# PRU_ICSSG0_PR1_ICSS_INTC_INTC_SLV register map
Vendor: Texas Instruments
Peripheral module from a debugger description file (folder am243x).
Registers are 32-bit, read-write, reset 0x0 unless marked. A register's access mark holds for its fields unless they carry their own. Offsets are as the file gives them; lines under a group give offsets from that group; [hi:lo] are bit positions; {n}, {i} and the like mark numbered series; 'fields as' and 'values as' point back to an identical list; <NAME> marks a mode.

## PRU_ICSSG0_PR1_ICSS_INTC_INTC_SLV
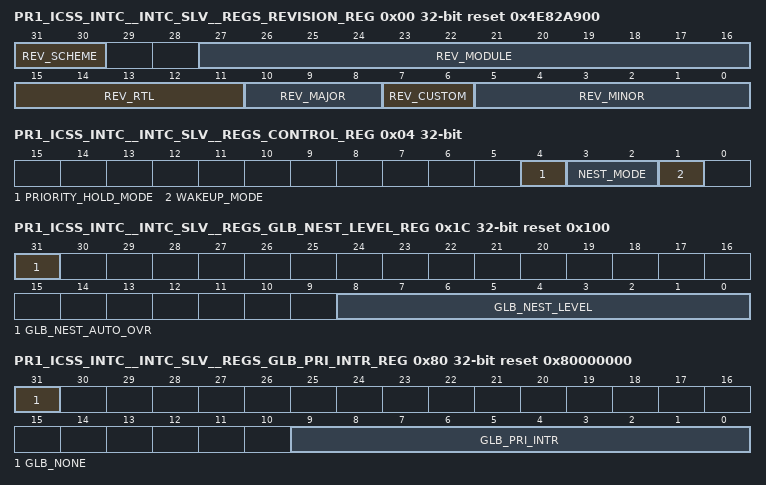
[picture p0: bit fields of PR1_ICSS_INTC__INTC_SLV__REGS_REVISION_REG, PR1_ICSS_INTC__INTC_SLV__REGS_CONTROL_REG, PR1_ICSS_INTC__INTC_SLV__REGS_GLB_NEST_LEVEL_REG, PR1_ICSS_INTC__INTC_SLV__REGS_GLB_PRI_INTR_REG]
0x00 PR1_ICSS_INTC__INTC_SLV__REGS_REVISION_REG ro reset 0x4E82A900
  [31:30] REV_SCHEME — Scheme
  [27:16] REV_MODULE — Module ID
  [15:11] REV_RTL — RTL revisions
  [10:8] REV_MAJOR — Major revision
  [7:6] REV_CUSTOM — Custom revision
  [5:0] REV_MINOR — Minor revision
0x04 PR1_ICSS_INTC__INTC_SLV__REGS_CONTROL_REG
  [4] PRIORITY_HOLD_MODE — Priority Holding Mode
  [3:2] NEST_MODE — Nesting Mode
  [1] WAKEUP_MODE — Wakeup mode enable
0x10 PR1_ICSS_INTC__INTC_SLV__REGS_GLOBAL_ENABLE_HINT_REG
  [0] ENABLE_HINT_ANY — Global Enable for all Host Ints
0x1C PR1_ICSS_INTC__INTC_SLV__REGS_GLB_NEST_LEVEL_REG access per field reset 0x100
  [31] GLB_NEST_AUTO_OVR wo — Global Nesting Level Override Automatic
  [8:0] GLB_NEST_LEVEL rw — Global Nesting Level
0x20 PR1_ICSS_INTC__INTC_SLV__REGS_STATUS_SET_INDEX_REG wo
  [9:0] STATUS_SET_INDEX — Status Set Index Register (write index to set status of)
0x24 PR1_ICSS_INTC__INTC_SLV__REGS_STATUS_CLR_INDEX_REG wo
  [9:0] STATUS_CLR_INDEX — Status Clear Index Register (write index to clear status of)
0x28 PR1_ICSS_INTC__INTC_SLV__REGS_ENABLE_SET_INDEX_REG access not given
  [9:0] ENABLE_SET_INDEX — Enable Set Index Register (write index to set enable of) (access W1TS)
0x2C PR1_ICSS_INTC__INTC_SLV__REGS_ENABLE_CLR_INDEX_REG access not given
  [9:0] ENABLE_CLR_INDEX — Enable Clear Index Register (write index to clear enable of) (access W1TC)
0x34 PR1_ICSS_INTC__INTC_SLV__REGS_HINT_ENABLE_SET_INDEX_REG access not given
  [9:0] HINT_ENABLE_SET_INDEX — Enable set for Host Interrupts (access W1TS)
0x38 PR1_ICSS_INTC__INTC_SLV__REGS_HINT_ENABLE_CLR_INDEX_REG access not given
  [9:0] HINT_ENABLE_CLR_INDEX — Enable clear for Host Interrupts (access W1TC)
0x80 PR1_ICSS_INTC__INTC_SLV__REGS_GLB_PRI_INTR_REG ro reset 0x80000000
  [31] GLB_NONE — No interrupt pending flag
  [9:0] GLB_PRI_INTR — Prioritized Interrupt
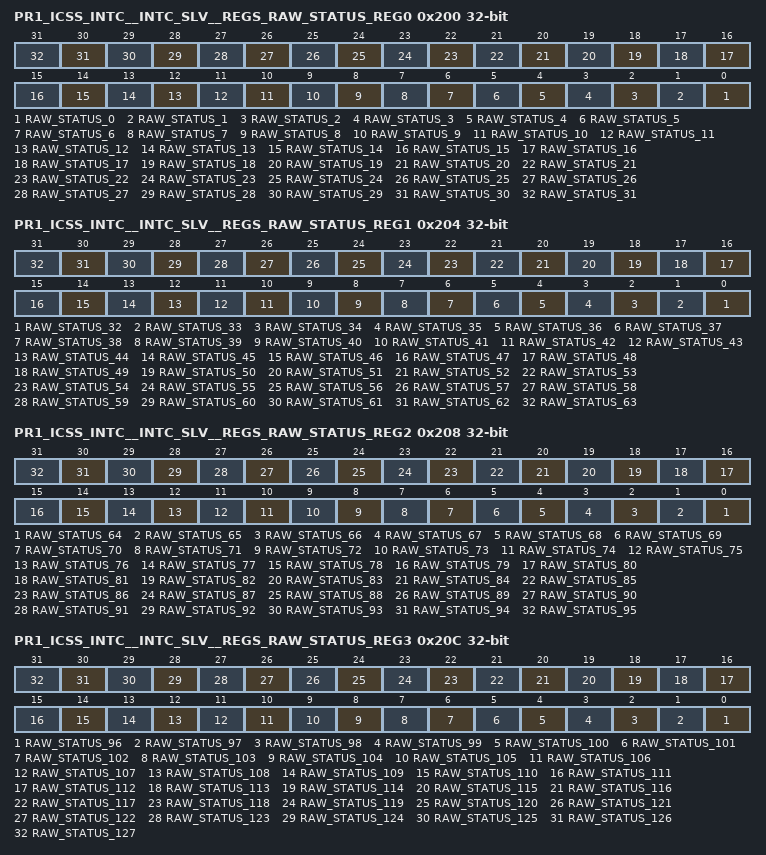
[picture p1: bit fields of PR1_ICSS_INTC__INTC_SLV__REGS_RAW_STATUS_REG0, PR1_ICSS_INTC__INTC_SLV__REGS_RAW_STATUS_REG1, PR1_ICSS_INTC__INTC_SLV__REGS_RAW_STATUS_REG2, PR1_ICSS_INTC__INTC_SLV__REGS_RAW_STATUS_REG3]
0x200 PR1_ICSS_INTC__INTC_SLV__REGS_RAW_STATUS_REG0 access not given
  [n] RAW_STATUS_{n} (n=0..31) — Raw Status (write 1 to set) for intr_in[{n}] (access W1TS)
0x204 PR1_ICSS_INTC__INTC_SLV__REGS_RAW_STATUS_REG1 access not given
  [n-32] RAW_STATUS_{n} (n=32..63) — Raw Status (write 1 to set) for intr_in[{n}] (access W1TS)
0x208 PR1_ICSS_INTC__INTC_SLV__REGS_RAW_STATUS_REG2 access not given
  [n-64] RAW_STATUS_{n} (n=64..95) — Raw Status (write 1 to set) for slv_events_in[{n-64}] (access W1TS)
0x20C PR1_ICSS_INTC__INTC_SLV__REGS_RAW_STATUS_REG3 access not given
  [n-96] RAW_STATUS_{n} (n=96..127) — Raw Status (write 1 to set) for slv_events_in[{n-64}] (access W1TS)
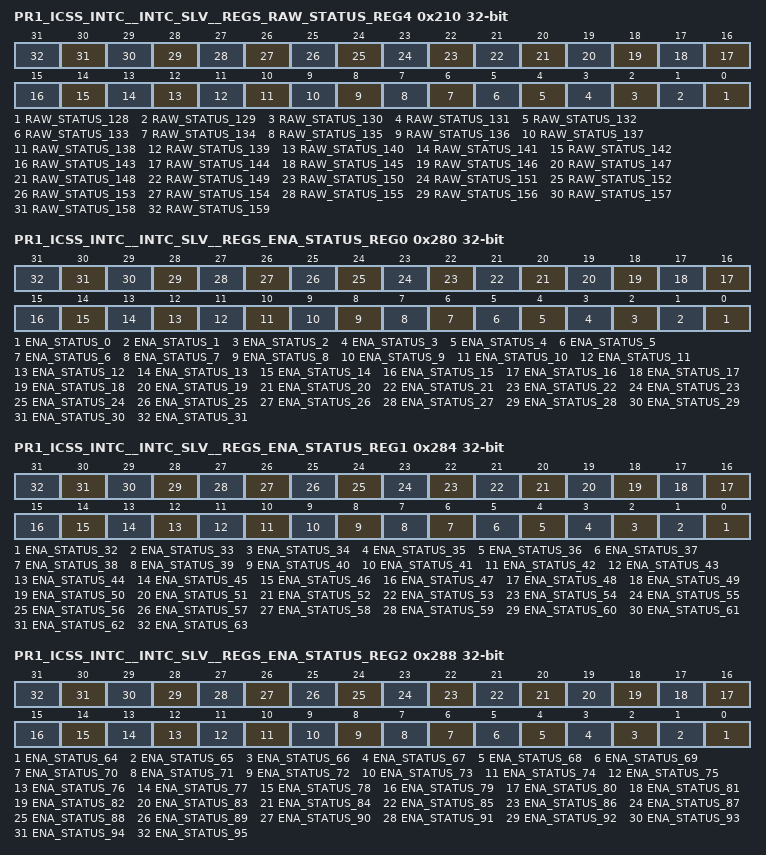
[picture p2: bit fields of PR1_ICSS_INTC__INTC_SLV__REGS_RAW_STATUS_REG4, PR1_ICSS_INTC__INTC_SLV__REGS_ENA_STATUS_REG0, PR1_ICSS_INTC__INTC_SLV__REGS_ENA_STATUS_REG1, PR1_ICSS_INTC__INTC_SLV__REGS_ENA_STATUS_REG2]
0x210 PR1_ICSS_INTC__INTC_SLV__REGS_RAW_STATUS_REG4 access not given
  [n-128] RAW_STATUS_{n} (n=128..159) — Raw Status (write 1 to set) for slv_events_in[{n-64}] (access W1TS)
0x280 PR1_ICSS_INTC__INTC_SLV__REGS_ENA_STATUS_REG0 access not given
  [n] ENA_STATUS_{n} (n=0..31) — Enabled Status for intr_in[{n}] (access W1TC)
0x284 PR1_ICSS_INTC__INTC_SLV__REGS_ENA_STATUS_REG1 access not given
  [n-32] ENA_STATUS_{n} (n=32..63) — Enabled Status for intr_in[{n}] (access W1TC)
0x288 PR1_ICSS_INTC__INTC_SLV__REGS_ENA_STATUS_REG2 access not given
  [n-64] ENA_STATUS_{n} (n=64..95) — Enabled Status for slv_events_in[{n-64}] (access W1TC)
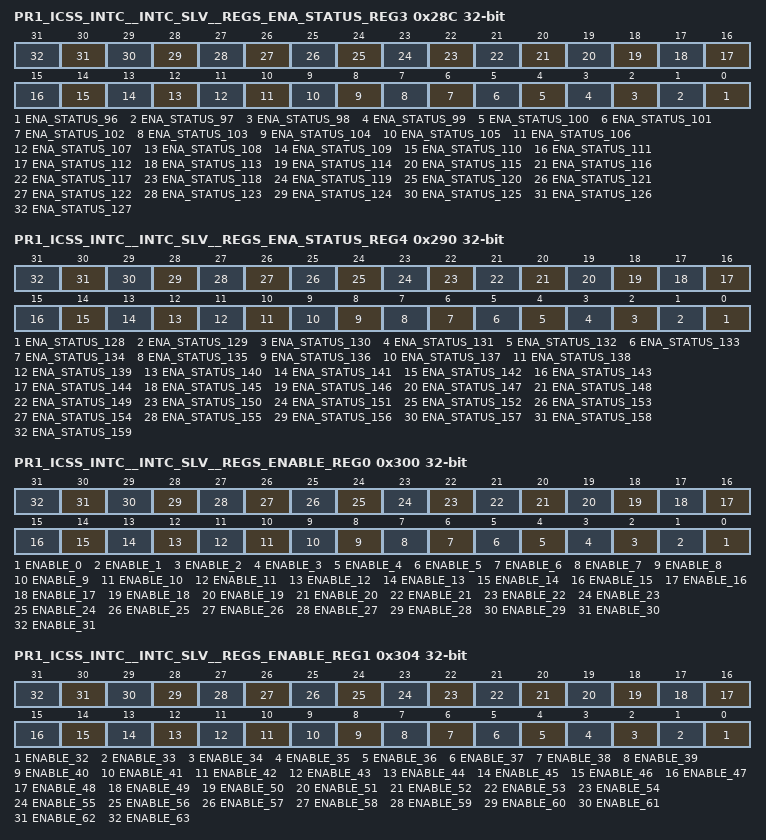
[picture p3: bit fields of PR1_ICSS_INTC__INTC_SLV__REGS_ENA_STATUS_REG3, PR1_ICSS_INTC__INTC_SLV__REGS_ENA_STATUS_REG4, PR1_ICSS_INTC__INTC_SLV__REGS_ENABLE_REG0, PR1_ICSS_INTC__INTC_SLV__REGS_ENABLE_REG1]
0x28C PR1_ICSS_INTC__INTC_SLV__REGS_ENA_STATUS_REG3 access not given
  [n-96] ENA_STATUS_{n} (n=96..127) — Enabled Status for slv_events_in[{n-64}] (access W1TC)
0x290 PR1_ICSS_INTC__INTC_SLV__REGS_ENA_STATUS_REG4 access not given
  [n-128] ENA_STATUS_{n} (n=128..159) — Enabled Status for slv_events_in[{n-64}] (access W1TC)
0x300 PR1_ICSS_INTC__INTC_SLV__REGS_ENABLE_REG0 access not given
  [n] ENABLE_{n} (n=0..31) — Enable (set) for intr_in[{n}] (access W1TS)
0x304 PR1_ICSS_INTC__INTC_SLV__REGS_ENABLE_REG1 access not given
  [n-32] ENABLE_{n} (n=32..63) — Enable (set) for intr_in[{n}] (access W1TS)
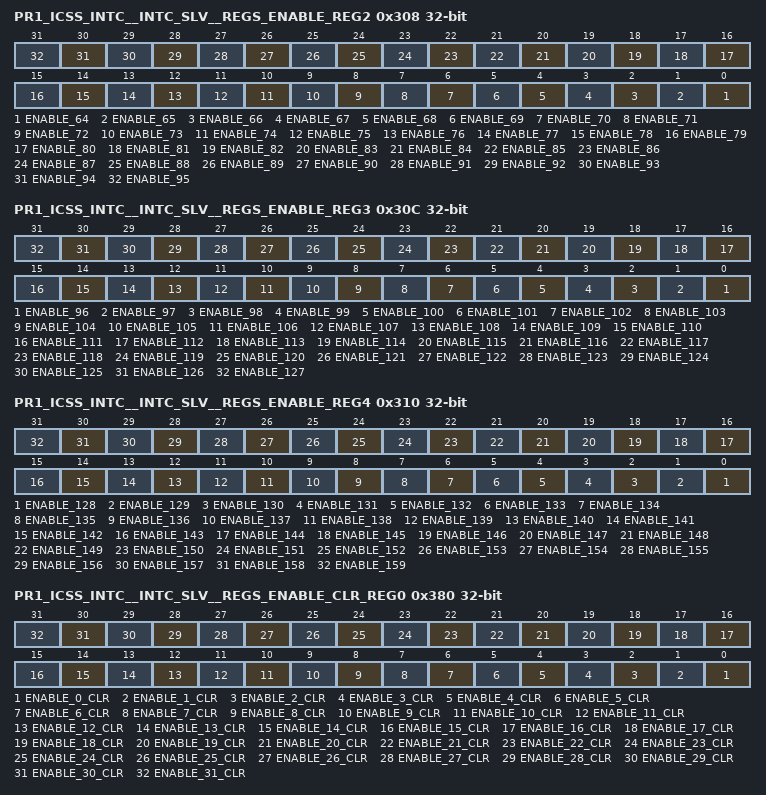
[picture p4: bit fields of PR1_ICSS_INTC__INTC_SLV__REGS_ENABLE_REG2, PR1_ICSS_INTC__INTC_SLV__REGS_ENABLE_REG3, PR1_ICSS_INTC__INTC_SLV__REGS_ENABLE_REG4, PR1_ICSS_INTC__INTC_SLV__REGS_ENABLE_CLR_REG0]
0x308 PR1_ICSS_INTC__INTC_SLV__REGS_ENABLE_REG2 access not given
  [n-64] ENABLE_{n} (n=64..95) — Enable (set) for slv_events_in[{n-64}] (access W1TS)
0x30C PR1_ICSS_INTC__INTC_SLV__REGS_ENABLE_REG3 access not given
  [n-96] ENABLE_{n} (n=96..127) — Enable (set) for slv_events_in[{n-64}] (access W1TS)
0x310 PR1_ICSS_INTC__INTC_SLV__REGS_ENABLE_REG4 access not given
  [n-128] ENABLE_{n} (n=128..159) — Enable (set) for slv_events_in[{n-64}] (access W1TS)
0x380 PR1_ICSS_INTC__INTC_SLV__REGS_ENABLE_CLR_REG0 access not given
  [n] ENABLE_{n}_CLR (n=0..31) — Enable clear for intr_in[{n}] (access W1TC)
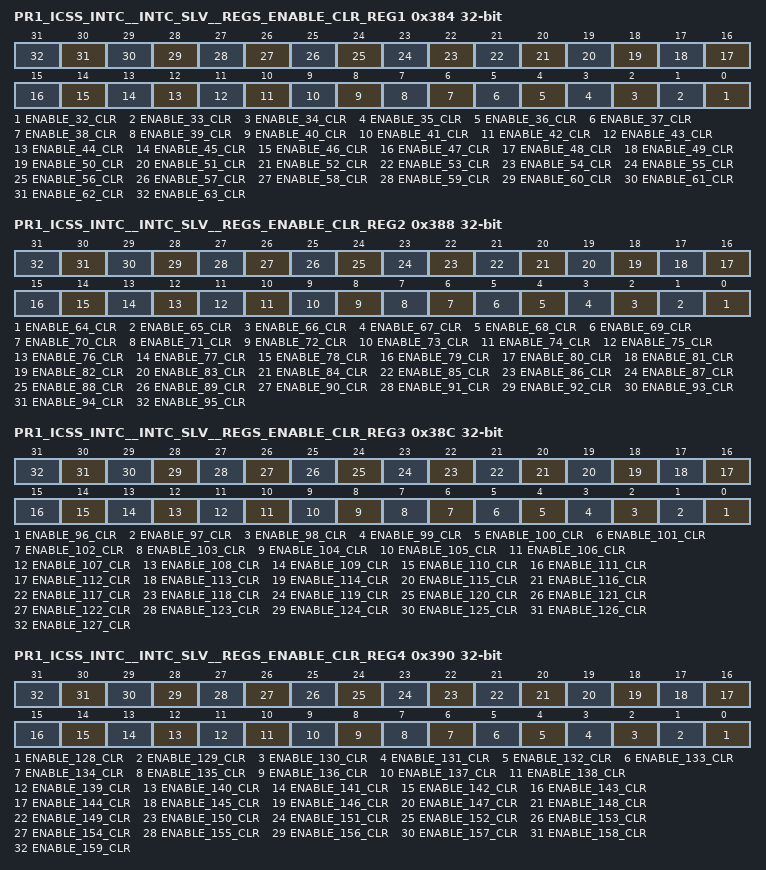
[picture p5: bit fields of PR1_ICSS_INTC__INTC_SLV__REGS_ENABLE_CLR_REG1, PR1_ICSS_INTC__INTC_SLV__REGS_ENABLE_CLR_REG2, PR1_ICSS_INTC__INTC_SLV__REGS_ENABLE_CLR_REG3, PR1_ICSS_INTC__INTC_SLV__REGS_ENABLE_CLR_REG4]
0x384 PR1_ICSS_INTC__INTC_SLV__REGS_ENABLE_CLR_REG1 access not given
  [n-32] ENABLE_{n}_CLR (n=32..63) — Enable clear for intr_in[{n}] (access W1TC)
0x388 PR1_ICSS_INTC__INTC_SLV__REGS_ENABLE_CLR_REG2 access not given
  [n-64] ENABLE_{n}_CLR (n=64..95) — Enable clear for slv_events_in[{n-64}] (access W1TC)
0x38C PR1_ICSS_INTC__INTC_SLV__REGS_ENABLE_CLR_REG3 access not given
  [n-96] ENABLE_{n}_CLR (n=96..127) — Enable clear for slv_events_in[{n-64}] (access W1TC)
0x390 PR1_ICSS_INTC__INTC_SLV__REGS_ENABLE_CLR_REG4 access not given
  [n-128] ENABLE_{n}_CLR (n=128..159) — Enable clear for slv_events_in[{n-64}] (access W1TC)
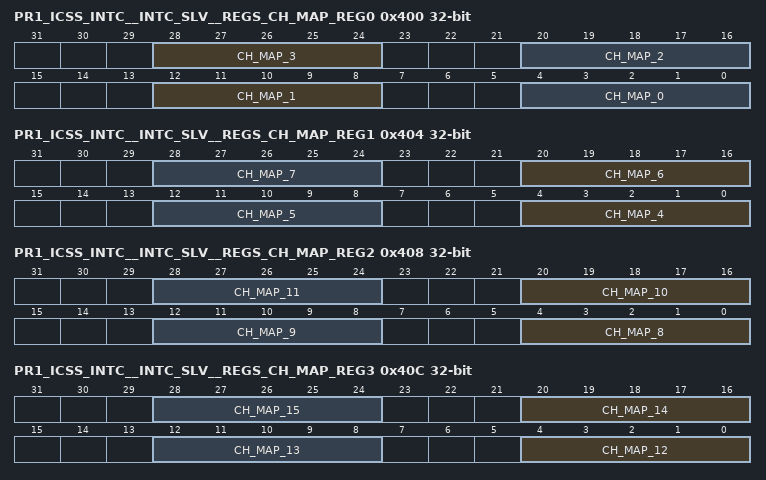
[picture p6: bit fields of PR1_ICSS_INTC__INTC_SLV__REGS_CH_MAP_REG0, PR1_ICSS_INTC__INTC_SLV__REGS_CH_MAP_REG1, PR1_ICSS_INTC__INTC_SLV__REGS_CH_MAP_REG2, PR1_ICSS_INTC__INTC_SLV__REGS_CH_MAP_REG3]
0x400 PR1_ICSS_INTC__INTC_SLV__REGS_CH_MAP_REG0 access per field
  [28:24] CH_MAP_3 rw — Interrupt Channel Map for intr_in[3]
  [20:16] CH_MAP_2 rw — Interrupt Channel Map for intr_in[2]
  [12:8] CH_MAP_1 rw — Interrupt Channel Map for intr_in[1]
  [4:0] CH_MAP_0 wo — Interrupt Channel Map for intr_in[0]
0x404 PR1_ICSS_INTC__INTC_SLV__REGS_CH_MAP_REG1
  [8n-28:8n-32] CH_MAP_{n} (n=4..7) — Interrupt Channel Map for intr_in[{n}]
0x408 PR1_ICSS_INTC__INTC_SLV__REGS_CH_MAP_REG2
  [8n-60:8n-64] CH_MAP_{n} (n=8..11) — Interrupt Channel Map for intr_in[{n}]
0x40C PR1_ICSS_INTC__INTC_SLV__REGS_CH_MAP_REG3
  [8n-92:8n-96] CH_MAP_{n} (n=12..15) — Interrupt Channel Map for intr_in[{n}]
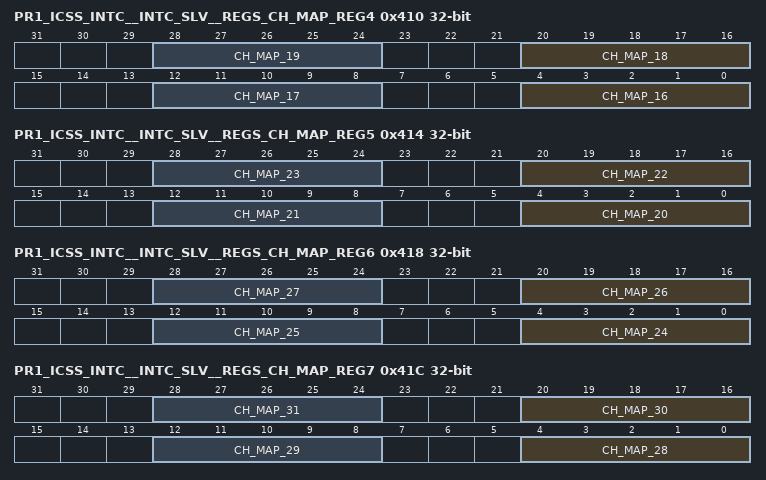
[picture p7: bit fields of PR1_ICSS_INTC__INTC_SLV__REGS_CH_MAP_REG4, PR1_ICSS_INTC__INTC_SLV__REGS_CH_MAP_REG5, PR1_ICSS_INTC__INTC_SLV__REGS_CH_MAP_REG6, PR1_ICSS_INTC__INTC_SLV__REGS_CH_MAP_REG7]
0x410 PR1_ICSS_INTC__INTC_SLV__REGS_CH_MAP_REG4
  [8n-124:8n-128] CH_MAP_{n} (n=16..19) — Interrupt Channel Map for intr_in[{n}]
0x414 PR1_ICSS_INTC__INTC_SLV__REGS_CH_MAP_REG5
  [8n-156:8n-160] CH_MAP_{n} (n=20..23) — Interrupt Channel Map for intr_in[{n}]
0x418 PR1_ICSS_INTC__INTC_SLV__REGS_CH_MAP_REG6
  [8n-188:8n-192] CH_MAP_{n} (n=24..27) — Interrupt Channel Map for intr_in[{n}]
0x41C PR1_ICSS_INTC__INTC_SLV__REGS_CH_MAP_REG7
  [8n-220:8n-224] CH_MAP_{n} (n=28..31) — Interrupt Channel Map for intr_in[{n}]
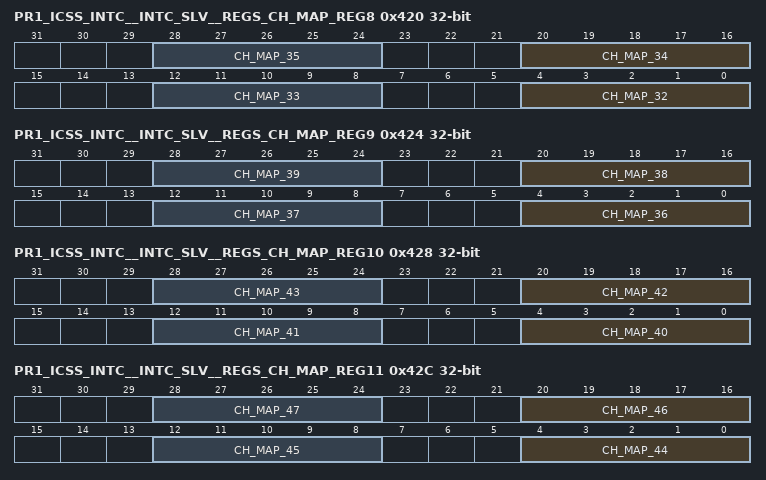
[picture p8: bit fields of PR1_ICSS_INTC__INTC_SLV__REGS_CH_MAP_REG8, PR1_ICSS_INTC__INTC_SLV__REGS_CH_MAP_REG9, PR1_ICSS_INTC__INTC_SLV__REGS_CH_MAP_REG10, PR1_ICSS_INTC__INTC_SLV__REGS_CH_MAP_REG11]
0x420 PR1_ICSS_INTC__INTC_SLV__REGS_CH_MAP_REG8
  [8n-252:8n-256] CH_MAP_{n} (n=32..35) — Interrupt Channel Map for intr_in[{n}]
0x424 PR1_ICSS_INTC__INTC_SLV__REGS_CH_MAP_REG9
  [8n-284:8n-288] CH_MAP_{n} (n=36..39) — Interrupt Channel Map for intr_in[{n}]
0x428 PR1_ICSS_INTC__INTC_SLV__REGS_CH_MAP_REG10
  [8n-316:8n-320] CH_MAP_{n} (n=40..43) — Interrupt Channel Map for intr_in[{n}]
0x42C PR1_ICSS_INTC__INTC_SLV__REGS_CH_MAP_REG11
  [8n-348:8n-352] CH_MAP_{n} (n=44..47) — Interrupt Channel Map for intr_in[{n}]
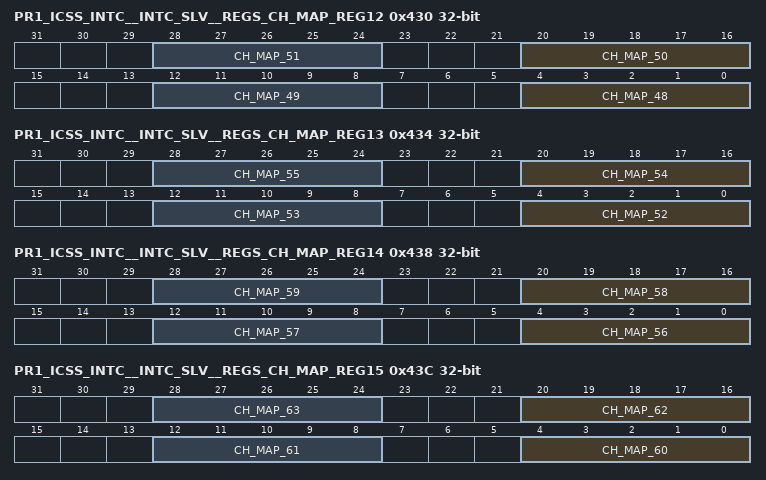
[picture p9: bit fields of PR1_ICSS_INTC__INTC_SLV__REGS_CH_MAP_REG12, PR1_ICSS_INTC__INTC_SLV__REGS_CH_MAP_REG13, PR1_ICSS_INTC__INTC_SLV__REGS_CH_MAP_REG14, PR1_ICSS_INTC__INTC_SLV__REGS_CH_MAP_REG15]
0x430 PR1_ICSS_INTC__INTC_SLV__REGS_CH_MAP_REG12
  [8n-380:8n-384] CH_MAP_{n} (n=48..51) — Interrupt Channel Map for intr_in[{n}]
0x434 PR1_ICSS_INTC__INTC_SLV__REGS_CH_MAP_REG13
  [8n-412:8n-416] CH_MAP_{n} (n=52..55) — Interrupt Channel Map for intr_in[{n}]
0x438 PR1_ICSS_INTC__INTC_SLV__REGS_CH_MAP_REG14
  [8n-444:8n-448] CH_MAP_{n} (n=56..59) — Interrupt Channel Map for intr_in[{n}]
0x43C PR1_ICSS_INTC__INTC_SLV__REGS_CH_MAP_REG15
  [8n-476:8n-480] CH_MAP_{n} (n=60..63) — Interrupt Channel Map for intr_in[{n}]
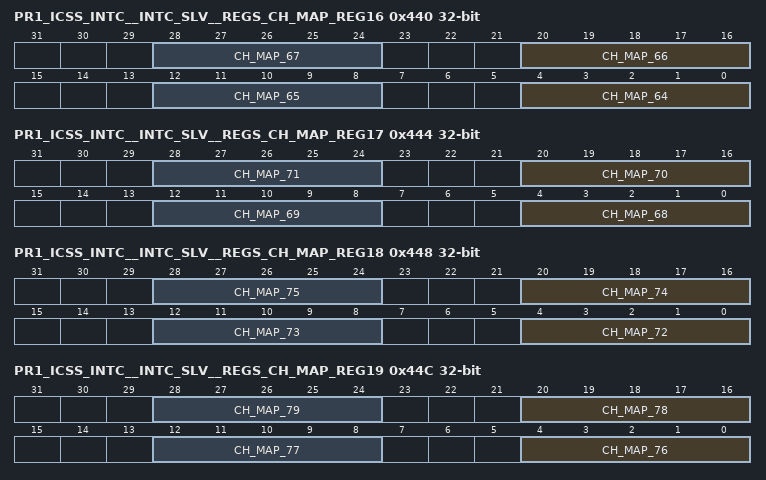
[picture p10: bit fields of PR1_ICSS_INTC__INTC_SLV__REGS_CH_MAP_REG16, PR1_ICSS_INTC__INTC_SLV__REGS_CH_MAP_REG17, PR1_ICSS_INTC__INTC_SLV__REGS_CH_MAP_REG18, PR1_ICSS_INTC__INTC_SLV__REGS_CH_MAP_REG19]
0x440 PR1_ICSS_INTC__INTC_SLV__REGS_CH_MAP_REG16
  [8n-508:8n-512] CH_MAP_{n} (n=64..67) — Interrupt Channel Map for slv_events_in[{n-64}]
0x444 PR1_ICSS_INTC__INTC_SLV__REGS_CH_MAP_REG17
  [8n-540:8n-544] CH_MAP_{n} (n=68..71) — Interrupt Channel Map for slv_events_in[{n-64}]
0x448 PR1_ICSS_INTC__INTC_SLV__REGS_CH_MAP_REG18
  [8n-572:8n-576] CH_MAP_{n} (n=72..75) — Interrupt Channel Map for slv_events_in[{n-64}]
0x44C PR1_ICSS_INTC__INTC_SLV__REGS_CH_MAP_REG19
  [8n-604:8n-608] CH_MAP_{n} (n=76..79) — Interrupt Channel Map for slv_events_in[{n-64}]
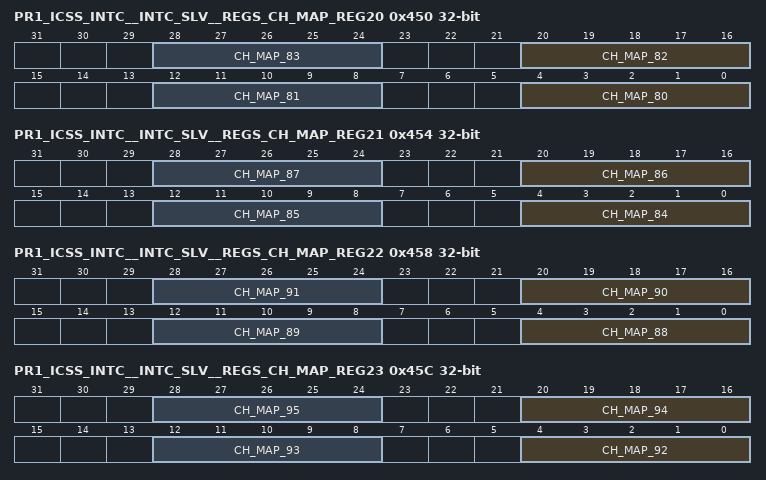
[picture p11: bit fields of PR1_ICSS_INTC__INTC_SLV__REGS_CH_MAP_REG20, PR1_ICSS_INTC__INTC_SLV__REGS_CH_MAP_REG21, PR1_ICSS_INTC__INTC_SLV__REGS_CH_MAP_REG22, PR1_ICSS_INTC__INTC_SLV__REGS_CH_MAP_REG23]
0x450 PR1_ICSS_INTC__INTC_SLV__REGS_CH_MAP_REG20
  [8n-636:8n-640] CH_MAP_{n} (n=80..83) — Interrupt Channel Map for slv_events_in[{n-64}]
0x454 PR1_ICSS_INTC__INTC_SLV__REGS_CH_MAP_REG21
  [8n-668:8n-672] CH_MAP_{n} (n=84..87) — Interrupt Channel Map for slv_events_in[{n-64}]
0x458 PR1_ICSS_INTC__INTC_SLV__REGS_CH_MAP_REG22
  [8n-700:8n-704] CH_MAP_{n} (n=88..91) — Interrupt Channel Map for slv_events_in[{n-64}]
0x45C PR1_ICSS_INTC__INTC_SLV__REGS_CH_MAP_REG23
  [8n-732:8n-736] CH_MAP_{n} (n=92..95) — Interrupt Channel Map for slv_events_in[{n-64}]
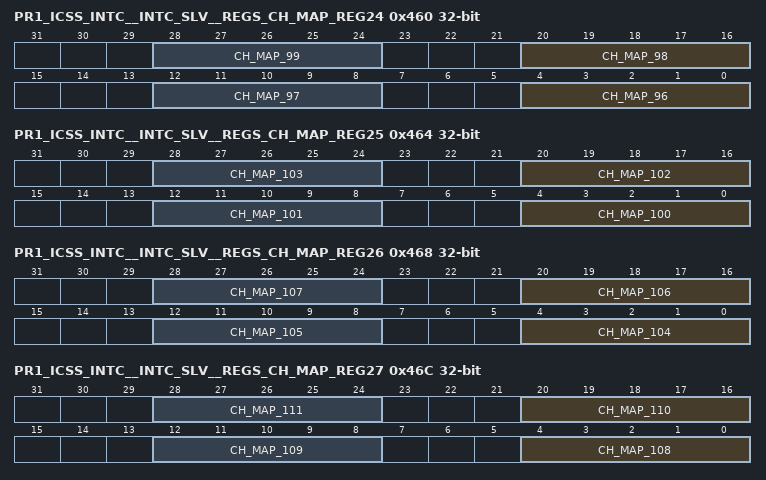
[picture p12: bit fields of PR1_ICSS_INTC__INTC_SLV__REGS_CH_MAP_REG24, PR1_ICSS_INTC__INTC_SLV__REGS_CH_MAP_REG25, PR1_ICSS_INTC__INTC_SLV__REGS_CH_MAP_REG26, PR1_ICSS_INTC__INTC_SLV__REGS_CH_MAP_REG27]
0x460 PR1_ICSS_INTC__INTC_SLV__REGS_CH_MAP_REG24
  [8n-764:8n-768] CH_MAP_{n} (n=96..99) — Interrupt Channel Map for slv_events_in[{n-64}]
0x464 PR1_ICSS_INTC__INTC_SLV__REGS_CH_MAP_REG25
  [8n-796:8n-800] CH_MAP_{n} (n=100..103) — Interrupt Channel Map for slv_events_in[{n-64}]
0x468 PR1_ICSS_INTC__INTC_SLV__REGS_CH_MAP_REG26
  [8n-828:8n-832] CH_MAP_{n} (n=104..107) — Interrupt Channel Map for slv_events_in[{n-64}]
0x46C PR1_ICSS_INTC__INTC_SLV__REGS_CH_MAP_REG27
  [8n-860:8n-864] CH_MAP_{n} (n=108..111) — Interrupt Channel Map for slv_events_in[{n-64}]
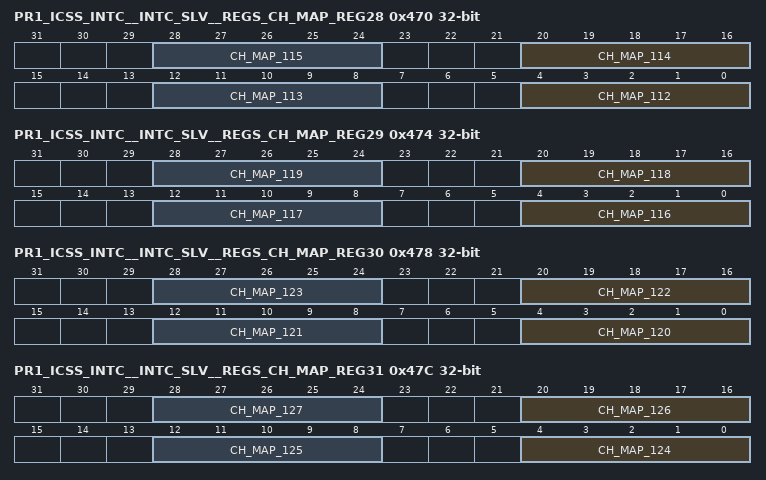
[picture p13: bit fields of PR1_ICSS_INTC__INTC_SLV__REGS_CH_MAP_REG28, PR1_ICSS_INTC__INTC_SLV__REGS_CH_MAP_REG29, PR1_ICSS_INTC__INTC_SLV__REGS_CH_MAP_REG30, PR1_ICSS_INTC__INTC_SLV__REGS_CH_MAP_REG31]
0x470 PR1_ICSS_INTC__INTC_SLV__REGS_CH_MAP_REG28
  [8n-892:8n-896] CH_MAP_{n} (n=112..115) — Interrupt Channel Map for slv_events_in[{n-64}]
0x474 PR1_ICSS_INTC__INTC_SLV__REGS_CH_MAP_REG29
  [8n-924:8n-928] CH_MAP_{n} (n=116..119) — Interrupt Channel Map for slv_events_in[{n-64}]
0x478 PR1_ICSS_INTC__INTC_SLV__REGS_CH_MAP_REG30
  [8n-956:8n-960] CH_MAP_{n} (n=120..123) — Interrupt Channel Map for slv_events_in[{n-64}]
0x47C PR1_ICSS_INTC__INTC_SLV__REGS_CH_MAP_REG31
  [8n-988:8n-992] CH_MAP_{n} (n=124..127) — Interrupt Channel Map for slv_events_in[{n-64}]
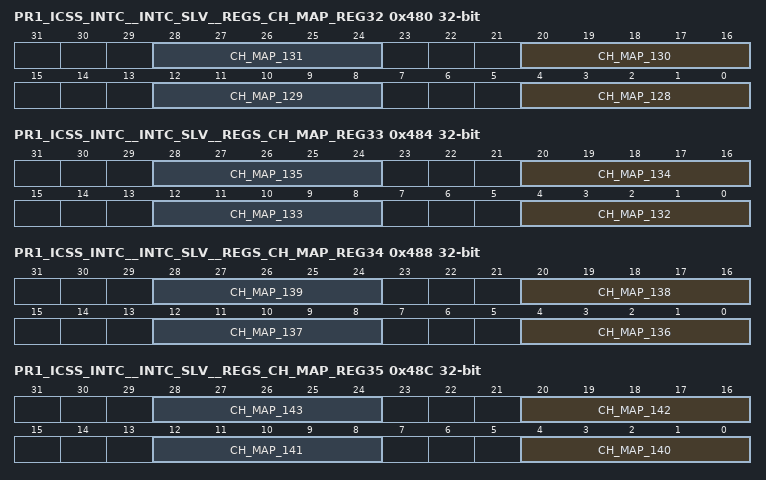
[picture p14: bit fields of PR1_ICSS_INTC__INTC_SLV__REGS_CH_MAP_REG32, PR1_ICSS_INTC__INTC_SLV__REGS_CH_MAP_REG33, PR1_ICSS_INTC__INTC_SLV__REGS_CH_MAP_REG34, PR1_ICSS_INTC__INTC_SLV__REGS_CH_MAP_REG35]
0x480 PR1_ICSS_INTC__INTC_SLV__REGS_CH_MAP_REG32
  [8n-1020:8n-1024] CH_MAP_{n} (n=128..131) — Interrupt Channel Map for slv_events_in[{n-64}]
0x484 PR1_ICSS_INTC__INTC_SLV__REGS_CH_MAP_REG33
  [8n-1052:8n-1056] CH_MAP_{n} (n=132..135) — Interrupt Channel Map for slv_events_in[{n-64}]
0x488 PR1_ICSS_INTC__INTC_SLV__REGS_CH_MAP_REG34
  [8n-1084:8n-1088] CH_MAP_{n} (n=136..139) — Interrupt Channel Map for slv_events_in[{n-64}]
0x48C PR1_ICSS_INTC__INTC_SLV__REGS_CH_MAP_REG35
  [8n-1116:8n-1120] CH_MAP_{n} (n=140..143) — Interrupt Channel Map for slv_events_in[{n-64}]
0x490 PR1_ICSS_INTC__INTC_SLV__REGS_CH_MAP_REG36
  [8n-1148:8n-1152] CH_MAP_{n} (n=144..147) — Interrupt Channel Map for slv_events_in[{n-64}]
0x494 PR1_ICSS_INTC__INTC_SLV__REGS_CH_MAP_REG37
  [8n-1180:8n-1184] CH_MAP_{n} (n=148..151) — Interrupt Channel Map for slv_events_in[{n-64}]
0x498 PR1_ICSS_INTC__INTC_SLV__REGS_CH_MAP_REG38
  [8n-1212:8n-1216] CH_MAP_{n} (n=152..155) — Interrupt Channel Map for slv_events_in[{n-64}]
0x49C PR1_ICSS_INTC__INTC_SLV__REGS_CH_MAP_REG39
  [8n-1244:8n-1248] CH_MAP_{n} (n=156..159) — Interrupt Channel Map for slv_events_in[{n-64}]
0x800 PR1_ICSS_INTC__INTC_SLV__REGS_HINT_MAP_REG0
  [8n+4:8n] HINT_MAP_{n} (n=0..3) — Host Interrupt Map for Channel {n}
0x804 PR1_ICSS_INTC__INTC_SLV__REGS_HINT_MAP_REG1
  [8n-28:8n-32] HINT_MAP_{n} (n=4..7) — Host Interrupt Map for Channel {n}
0x808 PR1_ICSS_INTC__INTC_SLV__REGS_HINT_MAP_REG2
  [8n-60:8n-64] HINT_MAP_{n} (n=8..11) — Host Interrupt Map for Channel {n}
0x80C PR1_ICSS_INTC__INTC_SLV__REGS_HINT_MAP_REG3
  [8n-92:8n-96] HINT_MAP_{n} (n=12..15) — Host Interrupt Map for Channel {n}
0x810 PR1_ICSS_INTC__INTC_SLV__REGS_HINT_MAP_REG4
  [8n-124:8n-128] HINT_MAP_{n} (n=16..19) — Host Interrupt Map for Channel {n}
{0x900+4i} PR1_ICSS_INTC__INTC_SLV__REGS_PRI_HINT_REG{i} ro reset 0x80000000 (i=0..19)
  [31] NONE_HINT_{i} — No interrupt pending flag
  [9:0] PRI_HINT_{i} — Host Int {i} Prioritized Interrupt
0xD00 PR1_ICSS_INTC__INTC_SLV__REGS_POLARITY_REG0 reset 0xFFFFFFFF
  [n] POLARITY_{n} (n=0..31) — Polarity for intr_in[{n}] 0=low
0xD04 PR1_ICSS_INTC__INTC_SLV__REGS_POLARITY_REG1 reset 0xFFFFFFFF
  [n-32] POLARITY_{n} (n=32..63) — Polarity for intr_in[{n}] 0=low
0xD08 PR1_ICSS_INTC__INTC_SLV__REGS_POLARITY_REG2 reset 0xFFFFFFFF
  [n-64] POLARITY_{n} (n=64..95) — Polarity for slv_events_in[{n-64}] 0=low
0xD0C PR1_ICSS_INTC__INTC_SLV__REGS_POLARITY_REG3 reset 0xFFFFFFFF
  [n-96] POLARITY_{n} (n=96..127) — Polarity for slv_events_in[{n-64}] 0=low
0xD10 PR1_ICSS_INTC__INTC_SLV__REGS_POLARITY_REG4 reset 0xFFFFFFFF
  [n-128] POLARITY_{n} (n=128..159) — Polarity for slv_events_in[{n-64}] 0=low
0xD80 PR1_ICSS_INTC__INTC_SLV__REGS_TYPE_REG0
  [n] TYPE_{n} (n=0..31) — Type for intr_in[{n}] 0=level
0xD84 PR1_ICSS_INTC__INTC_SLV__REGS_TYPE_REG1
  [n-32] TYPE_{n} (n=32..63) — Type for intr_in[{n}] 0=level
0xD88 PR1_ICSS_INTC__INTC_SLV__REGS_TYPE_REG2
  [n-64] TYPE_{n} (n=64..95) — Type for slv_events_in[{n-64}] 0=level
0xD8C PR1_ICSS_INTC__INTC_SLV__REGS_TYPE_REG3
  [n-96] TYPE_{n} (n=96..127) — Type for slv_events_in[{n-64}] 0=level
0xD90 PR1_ICSS_INTC__INTC_SLV__REGS_TYPE_REG4
  [n-128] TYPE_{n} (n=128..159) — Type for slv_events_in[{n-64}] 0=level
{0x1100+4i} PR1_ICSS_INTC__INTC_SLV__REGS_NEST_LEVEL_REG{i} access per field reset 0x100 (i=0..19)
  [31] NEST_AUTO_OVR wo — Nesting Level Override Automatic
  [8:0] NEST_HINT_{i} rw — Host Int {i} Nesting Level
0x1500 PR1_ICSS_INTC__INTC_SLV__REGS_ENABLE_HINT_REG0
  [n] ENABLE_HINT_{n} (n=0..19) — Enable for Host Int {n}
